# MIK32 register map
Vendor: Mikron JSC; Series: MIK32; File version: 1.0
Registers are 32-bit, read-write, reset 0x0 unless marked. A register's access mark holds for its fields unless they carry their own. Offsets are from the block's base; [hi:lo] are bit positions.

## TIMER32_0 — Регистры модуля TIMER32_0
Base 0x00050800
0x00 VALUE ro — Текущее значение основного таймера
  [31:0] TIM_VAL — Текущее значение счётчика
0x04 TOP reset 0xFFFFFFFF — максимальное значение счётной последовательности
  [31:0] TIM_TOP — максимальное значение счётчика (ограничивает счётную последоваельность сверху)
0x08 PRESCALE — значение делителя
  [31:0] TIM_PRESCALE — Значение предварительного делителя. Предделитель вырабатывает тактовый сигнал для счёта, частота которого в целое число раз меньше входной
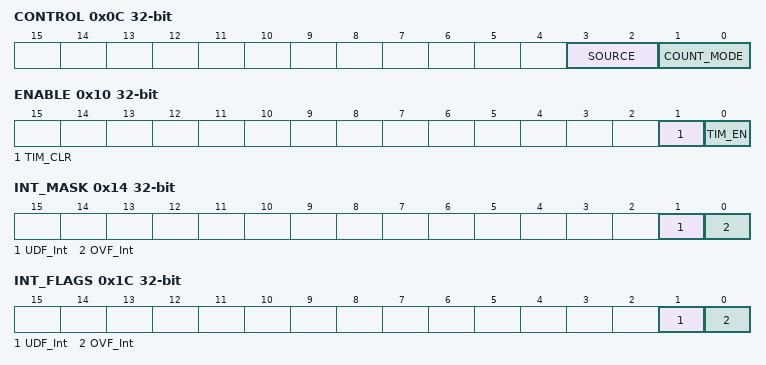
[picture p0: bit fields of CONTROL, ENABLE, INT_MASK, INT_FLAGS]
0x0C CONTROL — Конфигурационный регистр основного таймера
  [3:2] SOURCE — Выбор источника тактового сигнала для счёта
    0=APB_M_CLK (частота тактов шины APB_M); 1=TIM1 (синхронный вход тактирования TIM1); 2=TIMER32_0_Tx (вход TIMER32_0_Tx микросхемы); 3=TIM2 (асинхронный вход тактирования TIM2)
  [1:0] COUNT_MODE — Режим счёта таймера
    0=Direct (Прямой режим); 1=Reverse (Обратный режим); 2=Bidirectional (Двунаправленный режим)
0x10 ENABLE — Регистр включения таймера
  [1] TIM_CLR write-once — Сброс (обнуление) текущего значения счётчика при записи «1»
  [0] TIM_EN — Запуск/остановка работы счётчика
    0=Disable (Счётчик выключен); 1=Enable (Счётчик работает)
0x14 INT_MASK — Регистр маски прерываний
  [1] UDF_Int — Маска прерывания опустошения счётчика
  [0] OVF_Int — Маска прерывания по переполнению счётчика
0x18 INT_CLEAR reset 0xFFFFFFFF — Регистр сброса флагов прерываний
0x1C INT_FLAGS ro — Регистр флагов прерываний
  [1] UDF_Int — Статус прерывания опустошения счётчика
  [0] OVF_Int — Статус прерывания по переполнению счётчика

## GPIO_0 — Модуль ввода/вывода
Base 0x00084000
Same registers: GPIO_1 0x00084400
0x00 SET — Текущее состояние выводов (STATE) / Установка в «1» (SET) При чтении – текущее состояние выводов. При записи «1» соответствующий биту вывод устанавливается в «1»
0x04 CLEAR — Текущее состояние запросов прерываний (IRQ_STATE) / Установка в «0» (CLEAR) При чтении – текущее состояние запросов прерываний. При записи «1» соответствующий биту вывод устанавливается в «0»
0x08 DIRECTION_OUT reset 0xFFFF — Установка направления выводов как выход При чтении – текущее направление выводов: 0 – выход; 1 – вход. Запись «1» устанавливает соответствующий вывод как «выход»
0x0C DIRECTION_IN reset 0xFFFF — Установка направления выводов как вход При чтении – текущее направление выводов: 0 – выход; 1 – вход. Запись «1» устанавливает соответствующий вывод как «вход»
0x10 OUTPUT — Выходной регистр Чтение возвращает содержимое выходного регистра независимо от текущего направления выводов Запись устанавливает значения всех битов выходного регистра
0x14 CONTROL — Тестовый режим Запись «1» в [0:0] разряд – включение тестового режима (выходы замкнуты на входы внутри модуля) Запись «0» в [0:0] разряд – нормальный режим

## GPIO_2 — Модуль ввода/вывода
Base 0x00084800
Registers as GPIO_0; these are added or differ:
0x08 DIRECTION_OUT reset 0xFF — Установка направления выводов как выход При чтении – текущее направление выводов: 0 – выход; 1 – вход. Запись «1» устанавливает соответствующий вывод как «выход»
0x0C DIRECTION_IN reset 0xFF — Установка направления выводов как вход При чтении – текущее направление выводов: 0 – выход; 1 – вход. Запись «1» устанавливает соответствующий вывод как «вход»

## DAC0 — Управление ЦАП
Base 0x00085000
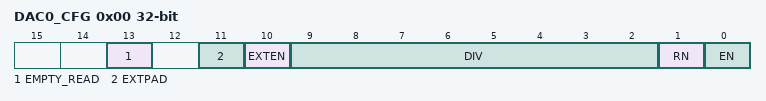
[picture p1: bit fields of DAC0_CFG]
0x00 DAC0_CFG — Регистр настройки ЦАП0
  [13] EMPTY_READ ro — Признак заполненности регистра DAC_VALUE
    0=Full (Значение, хранящееся в DAC_VALUE было сдвинуто в ЦАП, возможна запись следующего значения); 1=Empty (В регистре DAC_Value находится необработанное значение. Автоматически сбрасывается при записи в DAC_Value)
  [11] EXTPAD — Выбор источника внешнего опорного напряжения
    0=Calibrated_voltage_reference (Настраиваемый ИОН); 1=REF_DAC_PIN (Внешний вывод REF_ADC_DAC (PORT1_11))
  [10] EXTEN — Выбор источника опорного напряжения
    0=Internal (Внутренний); 1=External (Внешний)
  [9:2] DIV — Значение делителя тактового сигнала. Частота определяется как Fцап=Fin/(DIV+1)
  [1] RN — Управление сбросом ЦАП, активный уровень «0»
  [0] EN — Управление питанием ЦАП
    0=Disable (Выключен); 1=Enable (Включён)
0x04 DAC0_VALUE — Входные данные для ЦАП0
  [11:0] VALUE — Входные данные для прерывания
